# K1921VG1T register map
Vendor: NIIET; Series: K1921VGx; File version: 2.8
CPU: other r0p1, little endian, MPU, FPU, 4 interrupt priority bits
Registers are 32-bit, read-write, reset 0x0 unless marked. A register's access mark holds for its fields unless they carry their own. Offsets are from the block's base; [hi:lo] are bit positions; lines under a group give offsets from that group; {n}, {i} and the like mark numbered series.

## FLASHM — Flash control registers
Base 0x50002000
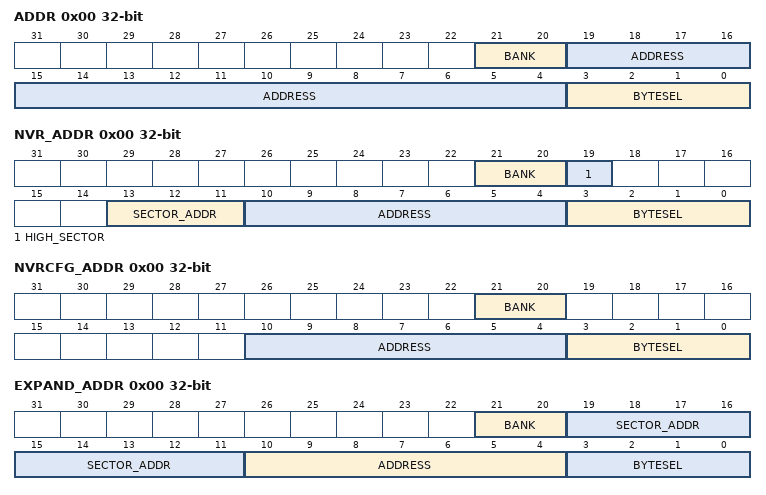
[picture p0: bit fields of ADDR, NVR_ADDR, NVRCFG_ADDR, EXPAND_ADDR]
0x00 ADDR — Address Register
  [21:20] BANK — Address value for flash operations (Bank number)
  [19:4] ADDRESS — Address value to selected flash IP
  [3:0] BYTESEL — Address value for each byte
0x00 NVR_ADDR (alternate view of ADDR) — Address Register for NVR access
  [21:20] BANK — Address value for flash operations (Bank number)
  [19] HIGH_SECTOR — Sector address value (msb) to selected flash IP
  [13:11] SECTOR_ADDR — Sector address value (lsb) to selected flash IP
  [10:4] ADDRESS — Address value within current sector to selected flash IP
  [3:0] BYTESEL — Address value for each byte
0x00 NVRCFG_ADDR (alternate view of NVR_ADDR) — Address Register for NVR_CFG access
  [21:20] BANK — Address value for flash operations (Bank number)
  [10:4] ADDRESS — Address value within current sector to selected flash IP
  [3:0] BYTESEL — Address value for each byte
0x00 EXPAND_ADDR (alternate view of NVRCFG_ADDR) — Address Register with expanded fields
  [21:20] BANK — Address value for flash operations (Bank number)
  [19:11] SECTOR_ADDR — Sector address value to selected flash IP
  [10:4] ADDRESS — Address value within current sector to selected flash IP
  [3:0] BYTESEL — Address value for each byte
{0x10+4i} DATA[{i}] (i=0..3) group
  0x00 VALUE reset 0xFFFFFFFF — Data Register
    [31:0] VAL — Data register value for flash operations
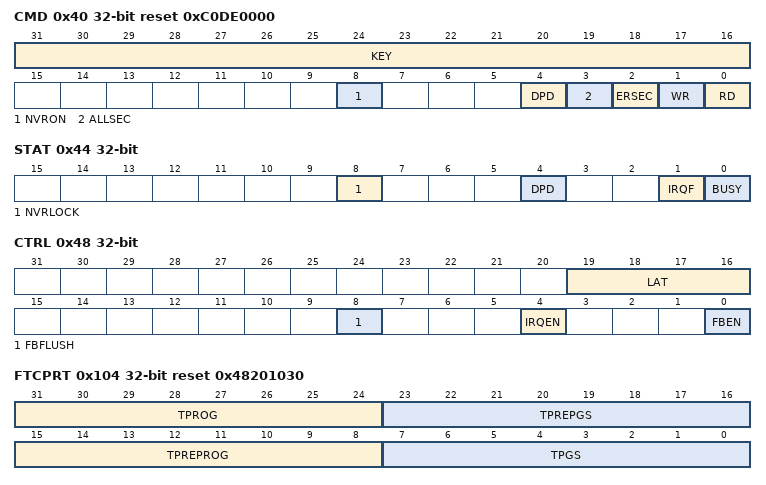
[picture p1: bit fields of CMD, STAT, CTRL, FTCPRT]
0x40 CMD reset 0xC0DE0000 — Command Register
  [31:16] KEY wo — Magic Key for flash access "C0DE"
    0xC0DE=Access (magic Key for flash access)
  [8] NVRON — NVR access bit
  [4] DPD — Enter/Exit power down mode
  [3] ALLSEC — Select all sectors for erase
  [2] ERSEC — Erase sector enable command
  [1] WR — Write enable command
  [0] RD — Read enable command
0x44 STAT — Status Register
  [8] NVRLOCK ro — If set NVR_CFG sector of flash is locked
  [4] DPD ro — Flash IP in powerdown mode
  [1] IRQF — IRQ Flag set when command done. Set by hardware only if IRQEN bit is set.
  [0] BUSY ro — Busy status bit when command is processing
0x48 CTRL — Control Register
  [19:16] LAT — Flash latency
  [8] FBFLUSH wo — Flush internal buffer
  [4] IRQEN — Interrupt enable bit
  [0] FBEN — Fetch buffer Enable
0x100 FTCETR reset 0xEA60 — Flash Timing Control register (Erase time)
  [31:0] TSCE — Erase time value in cycles
0x104 FTCPRT reset 0x48201030 — Flash Timing Control register (Program time)
  [31:24] TPROG — Program time value in cycles
  [23:16] TPREPGS — PREPG to PROG2 time value in cycles
  [15:8] TPREPROG — Pre-program time value in cycles
  [7:0] TPGS — Web to PROG2 high time value in cycles
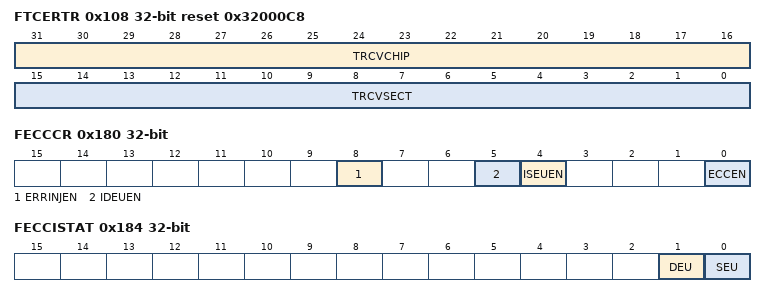
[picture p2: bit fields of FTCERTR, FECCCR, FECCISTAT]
0x108 FTCERTR reset 0x32000C8 — Flash Timing Control register (Erase Recovery time)
  [31:16] TRCVCHIP — Chip erase recovery time value in cycles
  [15:0] TRCVSECT — Sector erase recovery time value in cycles
0x10C FTCPRTR reset 0x14 — Flash Timing Control register (Program Recovery time)
  [7:0] TRCVPROG — Program recovery time value in cycles
{0x170+4i} ERRMASK[{i}] (i=0..3) group
  0x00 VALUE — Flash Data Mask Register
    [31:0] VAL — Corresponding bit of 32-bit write data bus is inverted
0x180 FECCCR — Flash ECC Control register
  [8] ERRINJEN — Enable error injection on write data bus
  [5] IDEUEN — Enable interrupt when double errors detected
  [4] ISEUEN — Enable interrupt when single error detected
  [0] ECCEN — Enable ECC detect and correction
0x184 FECCISTAT — Flash ECC Interrupt Status register
  [1] DEU — Double error occurred
  [0] SEU — Single error occurred
0x190 FECCSEC — Flash ECC Single Error Counter register
  [31:0] VAL — Single error times occurred
0x194 FECCDEC — Flash ECC Double Error Counter register
  [31:0] VAL — Double error times occurred
0x198 FECCSEA — Flash ECC Single Error Address register
  [31:0] VAL — Last latched address when single error occurred
0x19C FECCDEA — Flash ECC Double Error Address register
  [31:0] VAL — Last latched address when double error occurred

## FLASHD — Flash control registers
Base 0x5000C000
Registers as FLASHM, without DATA[*], ERRMASK[*]; these are added or differ:
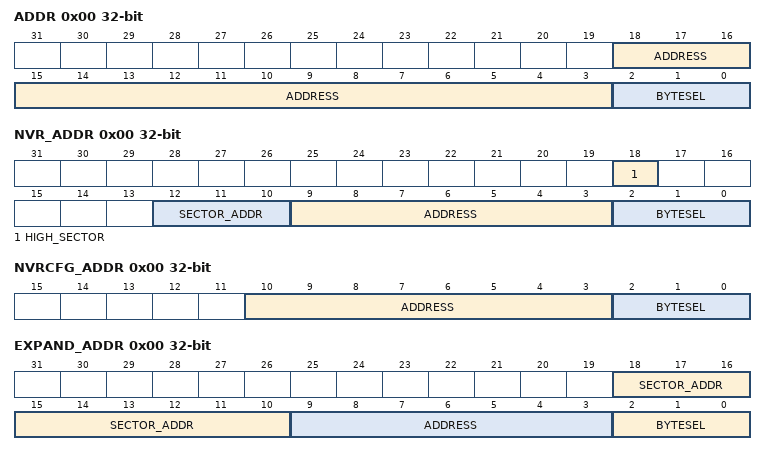
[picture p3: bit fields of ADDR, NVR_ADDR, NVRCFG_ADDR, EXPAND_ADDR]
0x00 ADDR — Address Register
  [18:3] ADDRESS — Address value to selected flash IP
  [2:0] BYTESEL — Address value for each byte
0x00 NVR_ADDR (alternate view of ADDR) — Address Register for NVR access
  [18] HIGH_SECTOR — Sector address value (msb) to selected flash IP
  [12:10] SECTOR_ADDR — Sector address value (lsb) to selected flash IP
  [9:3] ADDRESS — Address value within current sector to selected flash IP
  [2:0] BYTESEL — Address value for each byte
0x00 NVRCFG_ADDR (alternate view of NVR_ADDR) — Address Register for NVR_CFG access
  [10:3] ADDRESS — Address value within current sector to selected flash IP
  [2:0] BYTESEL — Address value for each byte
0x00 EXPAND_ADDR (alternate view of NVRCFG_ADDR) — Address Register with expanded fields
  [18:10] SECTOR_ADDR — Sector address value to selected flash IP
  [9:3] ADDRESS — Address value within current sector to selected flash IP
  [2:0] BYTESEL — Address value for each byte
{0x10+4i} DATA[{i}] (i=0..1) group
  0x00 VALUE reset 0xFFFFFFFF — Data Register
    [31:0] VAL — Data register value for flash operations
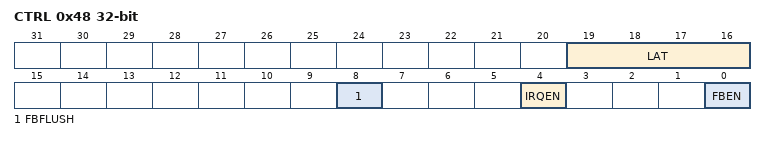
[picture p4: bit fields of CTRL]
0x48 CTRL — Control Register
  [19:16] LAT — Flash latency
  [8] FBFLUSH wo — Flush internal buffer
  [4] IRQEN — Command Interrupt enable bit
  [0] FBEN — Fetch buffer Enable
{0x170+4i} ERRMASK[{i}] (i=0..1) group
  0x00 VALUE — Flash Data Mask Register
    [31:0] VAL — Corresponding bit of 32-bit write data bus is inverted
